# STM32U5G7 register map
File version: 1.3
CPU: CM33 r0p1, little endian, MPU, FPU, 4 interrupt priority bits
Registers are 32-bit, read-write, reset 0x0 unless marked. A register's access mark holds for its fields unless they carry their own. Offsets are from the block's base; [hi:lo] are bit positions; {n}, {i} and the like mark numbered series; 'fields as' and 'values as' point back to an identical list.

## JPEG (part 3 of 3) — JPEG address block description
Base 0x4002A000
Same registers: SEC_JPEG 0x5002A000
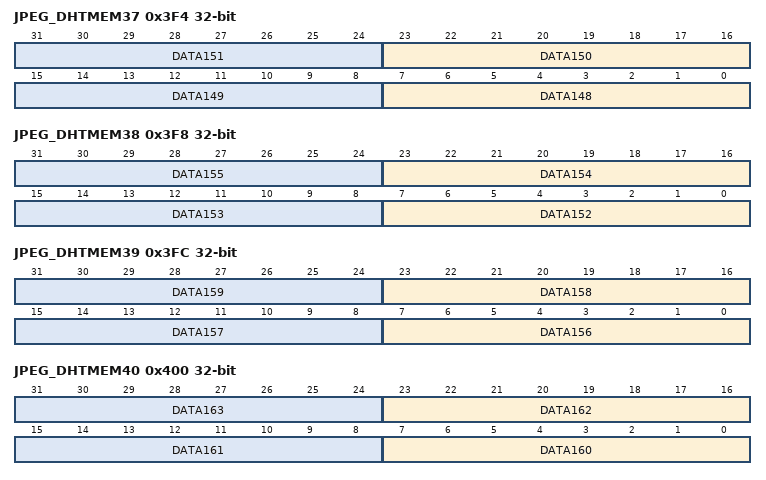
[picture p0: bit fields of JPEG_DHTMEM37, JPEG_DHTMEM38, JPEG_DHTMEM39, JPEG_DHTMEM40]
0x3F4 JPEG_DHTMEM37 reset not defined — For encoding process with header generation, this memory stores the DHT marker segment AC and DC Huffman tables in the ISO/IEC specification format: - DATA0 to DATA27: DC Huffman table0 - DATA28 to DATA205: AC Huffman table0 - DATA206 to DATA233: DC Huffman table1 - DATA234 to DATA411: AC Huffman table1
  [8n-1177:8n-1184] DATA{n} (n=148..151) — Huffman table data {n} Huffman table data for DHT marker segment generation.
0x3F8 JPEG_DHTMEM38 reset not defined — For encoding process with header generation, this memory stores the DHT marker segment AC and DC Huffman tables in the ISO/IEC specification format: - DATA0 to DATA27: DC Huffman table0 - DATA28 to DATA205: AC Huffman table0 - DATA206 to DATA233: DC Huffman table1 - DATA234 to DATA411: AC Huffman table1
  [8n-1209:8n-1216] DATA{n} (n=152..155) — Huffman table data {n} Huffman table data for DHT marker segment generation.
0x3FC JPEG_DHTMEM39 reset not defined — For encoding process with header generation, this memory stores the DHT marker segment AC and DC Huffman tables in the ISO/IEC specification format: - DATA0 to DATA27: DC Huffman table0 - DATA28 to DATA205: AC Huffman table0 - DATA206 to DATA233: DC Huffman table1 - DATA234 to DATA411: AC Huffman table1
  [8n-1241:8n-1248] DATA{n} (n=156..159) — Huffman table data {n} Huffman table data for DHT marker segment generation.
0x400 JPEG_DHTMEM40 reset not defined — For encoding process with header generation, this memory stores the DHT marker segment AC and DC Huffman tables in the ISO/IEC specification format: - DATA0 to DATA27: DC Huffman table0 - DATA28 to DATA205: AC Huffman table0 - DATA206 to DATA233: DC Huffman table1 - DATA234 to DATA411: AC Huffman table1
  [8n-1273:8n-1280] DATA{n} (n=160..163) — Huffman table data {n} Huffman table data for DHT marker segment generation.
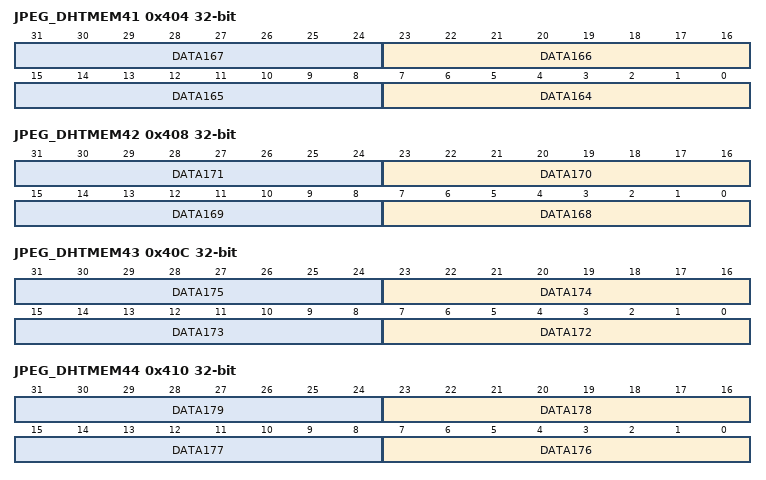
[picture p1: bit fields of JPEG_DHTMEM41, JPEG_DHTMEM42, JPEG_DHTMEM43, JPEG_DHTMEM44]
0x404 JPEG_DHTMEM41 reset not defined — For encoding process with header generation, this memory stores the DHT marker segment AC and DC Huffman tables in the ISO/IEC specification format: - DATA0 to DATA27: DC Huffman table0 - DATA28 to DATA205: AC Huffman table0 - DATA206 to DATA233: DC Huffman table1 - DATA234 to DATA411: AC Huffman table1
  [8n-1305:8n-1312] DATA{n} (n=164..167) — Huffman table data {n} Huffman table data for DHT marker segment generation.
0x408 JPEG_DHTMEM42 reset not defined — For encoding process with header generation, this memory stores the DHT marker segment AC and DC Huffman tables in the ISO/IEC specification format: - DATA0 to DATA27: DC Huffman table0 - DATA28 to DATA205: AC Huffman table0 - DATA206 to DATA233: DC Huffman table1 - DATA234 to DATA411: AC Huffman table1
  [8n-1337:8n-1344] DATA{n} (n=168..171) — Huffman table data {n} Huffman table data for DHT marker segment generation.
0x40C JPEG_DHTMEM43 reset not defined — For encoding process with header generation, this memory stores the DHT marker segment AC and DC Huffman tables in the ISO/IEC specification format: - DATA0 to DATA27: DC Huffman table0 - DATA28 to DATA205: AC Huffman table0 - DATA206 to DATA233: DC Huffman table1 - DATA234 to DATA411: AC Huffman table1
  [8n-1369:8n-1376] DATA{n} (n=172..175) — Huffman table data {n} Huffman table data for DHT marker segment generation.
0x410 JPEG_DHTMEM44 reset not defined — For encoding process with header generation, this memory stores the DHT marker segment AC and DC Huffman tables in the ISO/IEC specification format: - DATA0 to DATA27: DC Huffman table0 - DATA28 to DATA205: AC Huffman table0 - DATA206 to DATA233: DC Huffman table1 - DATA234 to DATA411: AC Huffman table1
  [8n-1401:8n-1408] DATA{n} (n=176..179) — Huffman table data {n} Huffman table data for DHT marker segment generation.
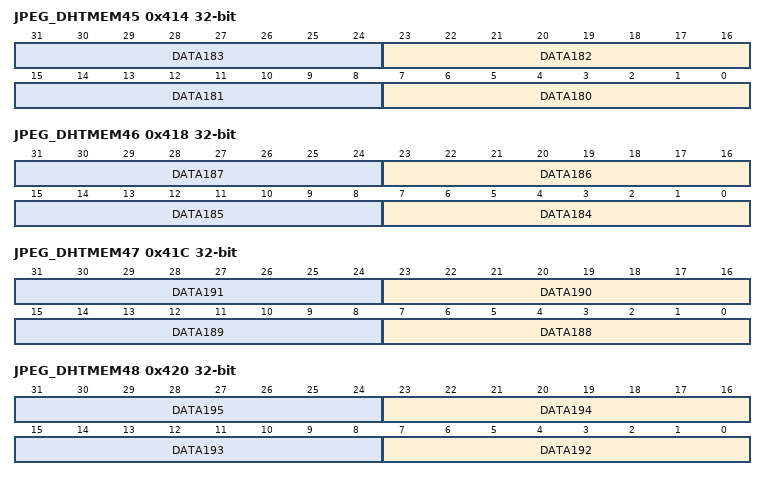
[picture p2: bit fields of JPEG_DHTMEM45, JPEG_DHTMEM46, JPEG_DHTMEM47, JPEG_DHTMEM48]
0x414 JPEG_DHTMEM45 reset not defined — For encoding process with header generation, this memory stores the DHT marker segment AC and DC Huffman tables in the ISO/IEC specification format: - DATA0 to DATA27: DC Huffman table0 - DATA28 to DATA205: AC Huffman table0 - DATA206 to DATA233: DC Huffman table1 - DATA234 to DATA411: AC Huffman table1
  [8n-1433:8n-1440] DATA{n} (n=180..183) — Huffman table data {n} Huffman table data for DHT marker segment generation.
0x418 JPEG_DHTMEM46 reset not defined — For encoding process with header generation, this memory stores the DHT marker segment AC and DC Huffman tables in the ISO/IEC specification format: - DATA0 to DATA27: DC Huffman table0 - DATA28 to DATA205: AC Huffman table0 - DATA206 to DATA233: DC Huffman table1 - DATA234 to DATA411: AC Huffman table1
  [8n-1465:8n-1472] DATA{n} (n=184..187) — Huffman table data {n} Huffman table data for DHT marker segment generation.
0x41C JPEG_DHTMEM47 reset not defined — For encoding process with header generation, this memory stores the DHT marker segment AC and DC Huffman tables in the ISO/IEC specification format: - DATA0 to DATA27: DC Huffman table0 - DATA28 to DATA205: AC Huffman table0 - DATA206 to DATA233: DC Huffman table1 - DATA234 to DATA411: AC Huffman table1
  [8n-1497:8n-1504] DATA{n} (n=188..191) — Huffman table data {n} Huffman table data for DHT marker segment generation.
0x420 JPEG_DHTMEM48 reset not defined — For encoding process with header generation, this memory stores the DHT marker segment AC and DC Huffman tables in the ISO/IEC specification format: - DATA0 to DATA27: DC Huffman table0 - DATA28 to DATA205: AC Huffman table0 - DATA206 to DATA233: DC Huffman table1 - DATA234 to DATA411: AC Huffman table1
  [8n-1529:8n-1536] DATA{n} (n=192..195) — Huffman table data {n} Huffman table data for DHT marker segment generation.
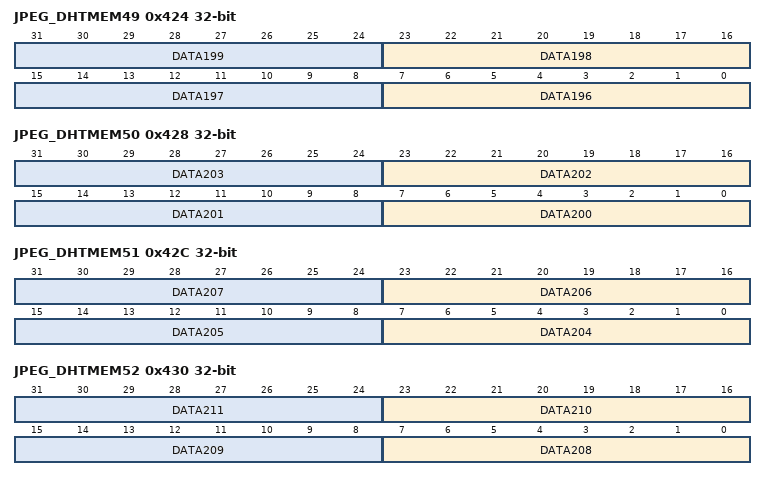
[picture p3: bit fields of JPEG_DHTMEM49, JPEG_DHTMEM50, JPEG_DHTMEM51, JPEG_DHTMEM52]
0x424 JPEG_DHTMEM49 reset not defined — For encoding process with header generation, this memory stores the DHT marker segment AC and DC Huffman tables in the ISO/IEC specification format: - DATA0 to DATA27: DC Huffman table0 - DATA28 to DATA205: AC Huffman table0 - DATA206 to DATA233: DC Huffman table1 - DATA234 to DATA411: AC Huffman table1
  [8n-1561:8n-1568] DATA{n} (n=196..199) — Huffman table data {n} Huffman table data for DHT marker segment generation.
0x428 JPEG_DHTMEM50 reset not defined — For encoding process with header generation, this memory stores the DHT marker segment AC and DC Huffman tables in the ISO/IEC specification format: - DATA0 to DATA27: DC Huffman table0 - DATA28 to DATA205: AC Huffman table0 - DATA206 to DATA233: DC Huffman table1 - DATA234 to DATA411: AC Huffman table1
  [8n-1593:8n-1600] DATA{n} (n=200..203) — Huffman table data {n} Huffman table data for DHT marker segment generation.
0x42C JPEG_DHTMEM51 reset not defined — For encoding process with header generation, this memory stores the DHT marker segment AC and DC Huffman tables in the ISO/IEC specification format: - DATA0 to DATA27: DC Huffman table0 - DATA28 to DATA205: AC Huffman table0 - DATA206 to DATA233: DC Huffman table1 - DATA234 to DATA411: AC Huffman table1
  [8n-1625:8n-1632] DATA{n} (n=204..207) — Huffman table data {n} Huffman table data for DHT marker segment generation.
0x430 JPEG_DHTMEM52 reset not defined — For encoding process with header generation, this memory stores the DHT marker segment AC and DC Huffman tables in the ISO/IEC specification format: - DATA0 to DATA27: DC Huffman table0 - DATA28 to DATA205: AC Huffman table0 - DATA206 to DATA233: DC Huffman table1 - DATA234 to DATA411: AC Huffman table1
  [8n-1657:8n-1664] DATA{n} (n=208..211) — Huffman table data {n} Huffman table data for DHT marker segment generation.
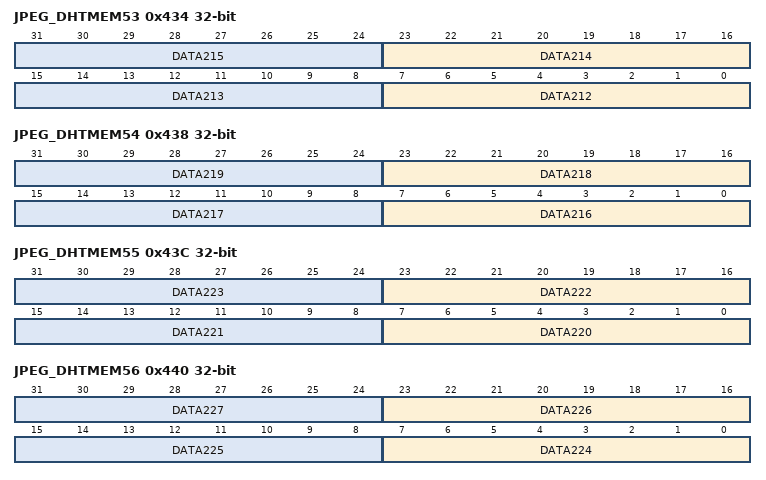
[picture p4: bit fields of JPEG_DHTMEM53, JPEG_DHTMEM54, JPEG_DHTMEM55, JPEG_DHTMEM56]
0x434 JPEG_DHTMEM53 reset not defined — For encoding process with header generation, this memory stores the DHT marker segment AC and DC Huffman tables in the ISO/IEC specification format: - DATA0 to DATA27: DC Huffman table0 - DATA28 to DATA205: AC Huffman table0 - DATA206 to DATA233: DC Huffman table1 - DATA234 to DATA411: AC Huffman table1
  [8n-1689:8n-1696] DATA{n} (n=212..215) — Huffman table data {n} Huffman table data for DHT marker segment generation.
0x438 JPEG_DHTMEM54 reset not defined — For encoding process with header generation, this memory stores the DHT marker segment AC and DC Huffman tables in the ISO/IEC specification format: - DATA0 to DATA27: DC Huffman table0 - DATA28 to DATA205: AC Huffman table0 - DATA206 to DATA233: DC Huffman table1 - DATA234 to DATA411: AC Huffman table1
  [8n-1721:8n-1728] DATA{n} (n=216..219) — Huffman table data {n} Huffman table data for DHT marker segment generation.
0x43C JPEG_DHTMEM55 reset not defined — For encoding process with header generation, this memory stores the DHT marker segment AC and DC Huffman tables in the ISO/IEC specification format: - DATA0 to DATA27: DC Huffman table0 - DATA28 to DATA205: AC Huffman table0 - DATA206 to DATA233: DC Huffman table1 - DATA234 to DATA411: AC Huffman table1
  [8n-1753:8n-1760] DATA{n} (n=220..223) — Huffman table data {n} Huffman table data for DHT marker segment generation.
0x440 JPEG_DHTMEM56 reset not defined — For encoding process with header generation, this memory stores the DHT marker segment AC and DC Huffman tables in the ISO/IEC specification format: - DATA0 to DATA27: DC Huffman table0 - DATA28 to DATA205: AC Huffman table0 - DATA206 to DATA233: DC Huffman table1 - DATA234 to DATA411: AC Huffman table1
  [8n-1785:8n-1792] DATA{n} (n=224..227) — Huffman table data {n} Huffman table data for DHT marker segment generation.
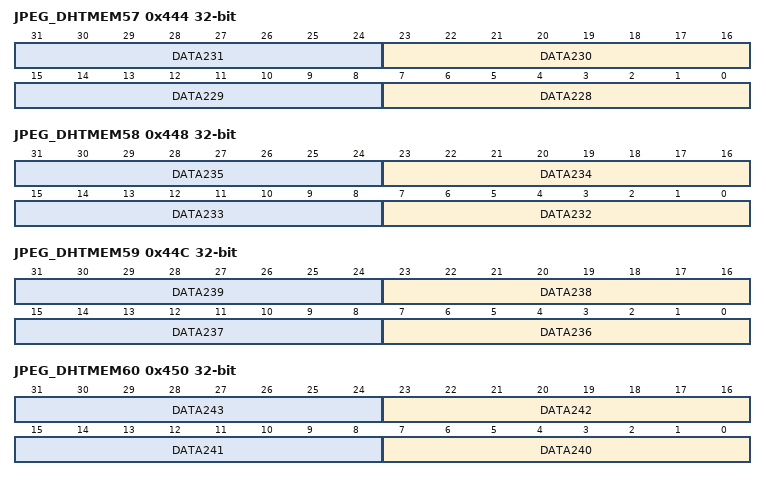
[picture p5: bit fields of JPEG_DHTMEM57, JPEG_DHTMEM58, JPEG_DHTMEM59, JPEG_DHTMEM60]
0x444 JPEG_DHTMEM57 reset not defined — For encoding process with header generation, this memory stores the DHT marker segment AC and DC Huffman tables in the ISO/IEC specification format: - DATA0 to DATA27: DC Huffman table0 - DATA28 to DATA205: AC Huffman table0 - DATA206 to DATA233: DC Huffman table1 - DATA234 to DATA411: AC Huffman table1
  [8n-1817:8n-1824] DATA{n} (n=228..231) — Huffman table data {n} Huffman table data for DHT marker segment generation.
0x448 JPEG_DHTMEM58 reset not defined — For encoding process with header generation, this memory stores the DHT marker segment AC and DC Huffman tables in the ISO/IEC specification format: - DATA0 to DATA27: DC Huffman table0 - DATA28 to DATA205: AC Huffman table0 - DATA206 to DATA233: DC Huffman table1 - DATA234 to DATA411: AC Huffman table1
  [8n-1849:8n-1856] DATA{n} (n=232..235) — Huffman table data {n} Huffman table data for DHT marker segment generation.
0x44C JPEG_DHTMEM59 reset not defined — For encoding process with header generation, this memory stores the DHT marker segment AC and DC Huffman tables in the ISO/IEC specification format: - DATA0 to DATA27: DC Huffman table0 - DATA28 to DATA205: AC Huffman table0 - DATA206 to DATA233: DC Huffman table1 - DATA234 to DATA411: AC Huffman table1
  [8n-1881:8n-1888] DATA{n} (n=236..239) — Huffman table data {n} Huffman table data for DHT marker segment generation.
0x450 JPEG_DHTMEM60 reset not defined — For encoding process with header generation, this memory stores the DHT marker segment AC and DC Huffman tables in the ISO/IEC specification format: - DATA0 to DATA27: DC Huffman table0 - DATA28 to DATA205: AC Huffman table0 - DATA206 to DATA233: DC Huffman table1 - DATA234 to DATA411: AC Huffman table1
  [8n-1913:8n-1920] DATA{n} (n=240..243) — Huffman table data {n} Huffman table data for DHT marker segment generation.
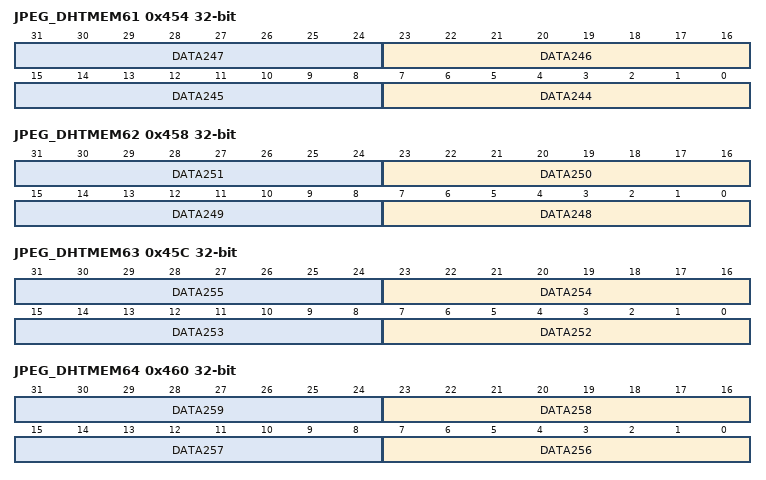
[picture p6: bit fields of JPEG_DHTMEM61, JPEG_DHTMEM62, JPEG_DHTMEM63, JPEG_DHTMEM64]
0x454 JPEG_DHTMEM61 reset not defined — For encoding process with header generation, this memory stores the DHT marker segment AC and DC Huffman tables in the ISO/IEC specification format: - DATA0 to DATA27: DC Huffman table0 - DATA28 to DATA205: AC Huffman table0 - DATA206 to DATA233: DC Huffman table1 - DATA234 to DATA411: AC Huffman table1
  [8n-1945:8n-1952] DATA{n} (n=244..247) — Huffman table data {n} Huffman table data for DHT marker segment generation.
0x458 JPEG_DHTMEM62 reset not defined — For encoding process with header generation, this memory stores the DHT marker segment AC and DC Huffman tables in the ISO/IEC specification format: - DATA0 to DATA27: DC Huffman table0 - DATA28 to DATA205: AC Huffman table0 - DATA206 to DATA233: DC Huffman table1 - DATA234 to DATA411: AC Huffman table1
  [8n-1977:8n-1984] DATA{n} (n=248..251) — Huffman table data {n} Huffman table data for DHT marker segment generation.
0x45C JPEG_DHTMEM63 reset not defined — For encoding process with header generation, this memory stores the DHT marker segment AC and DC Huffman tables in the ISO/IEC specification format: - DATA0 to DATA27: DC Huffman table0 - DATA28 to DATA205: AC Huffman table0 - DATA206 to DATA233: DC Huffman table1 - DATA234 to DATA411: AC Huffman table1
  [8n-2009:8n-2016] DATA{n} (n=252..255) — Huffman table data {n} Huffman table data for DHT marker segment generation.
0x460 JPEG_DHTMEM64 reset not defined — For encoding process with header generation, this memory stores the DHT marker segment AC and DC Huffman tables in the ISO/IEC specification format: - DATA0 to DATA27: DC Huffman table0 - DATA28 to DATA205: AC Huffman table0 - DATA206 to DATA233: DC Huffman table1 - DATA234 to DATA411: AC Huffman table1
  [8n-2041:8n-2048] DATA{n} (n=256..259) — Huffman table data {n} Huffman table data for DHT marker segment generation.
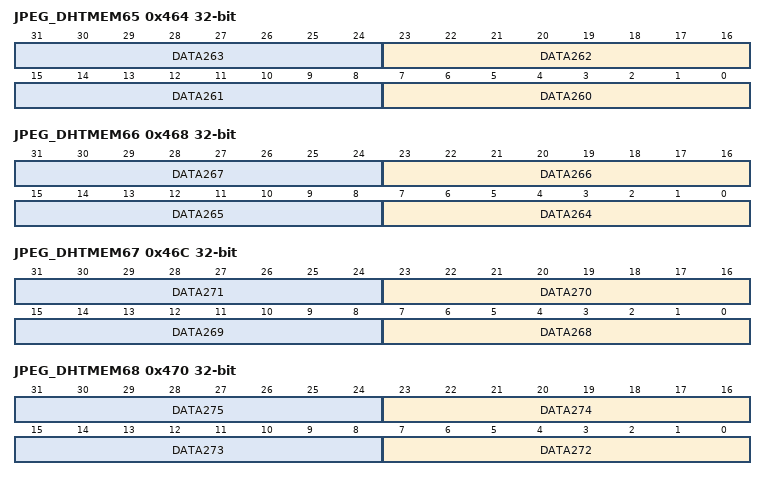
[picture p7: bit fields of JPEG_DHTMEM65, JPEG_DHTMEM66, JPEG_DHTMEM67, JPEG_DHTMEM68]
0x464 JPEG_DHTMEM65 reset not defined — For encoding process with header generation, this memory stores the DHT marker segment AC and DC Huffman tables in the ISO/IEC specification format: - DATA0 to DATA27: DC Huffman table0 - DATA28 to DATA205: AC Huffman table0 - DATA206 to DATA233: DC Huffman table1 - DATA234 to DATA411: AC Huffman table1
  [8n-2073:8n-2080] DATA{n} (n=260..263) — Huffman table data {n} Huffman table data for DHT marker segment generation.
0x468 JPEG_DHTMEM66 reset not defined — For encoding process with header generation, this memory stores the DHT marker segment AC and DC Huffman tables in the ISO/IEC specification format: - DATA0 to DATA27: DC Huffman table0 - DATA28 to DATA205: AC Huffman table0 - DATA206 to DATA233: DC Huffman table1 - DATA234 to DATA411: AC Huffman table1
  [8n-2105:8n-2112] DATA{n} (n=264..267) — Huffman table data {n} Huffman table data for DHT marker segment generation.
0x46C JPEG_DHTMEM67 reset not defined — For encoding process with header generation, this memory stores the DHT marker segment AC and DC Huffman tables in the ISO/IEC specification format: - DATA0 to DATA27: DC Huffman table0 - DATA28 to DATA205: AC Huffman table0 - DATA206 to DATA233: DC Huffman table1 - DATA234 to DATA411: AC Huffman table1
  [8n-2137:8n-2144] DATA{n} (n=268..271) — Huffman table data {n} Huffman table data for DHT marker segment generation.
0x470 JPEG_DHTMEM68 reset not defined — For encoding process with header generation, this memory stores the DHT marker segment AC and DC Huffman tables in the ISO/IEC specification format: - DATA0 to DATA27: DC Huffman table0 - DATA28 to DATA205: AC Huffman table0 - DATA206 to DATA233: DC Huffman table1 - DATA234 to DATA411: AC Huffman table1
  [8n-2169:8n-2176] DATA{n} (n=272..275) — Huffman table data {n} Huffman table data for DHT marker segment generation.
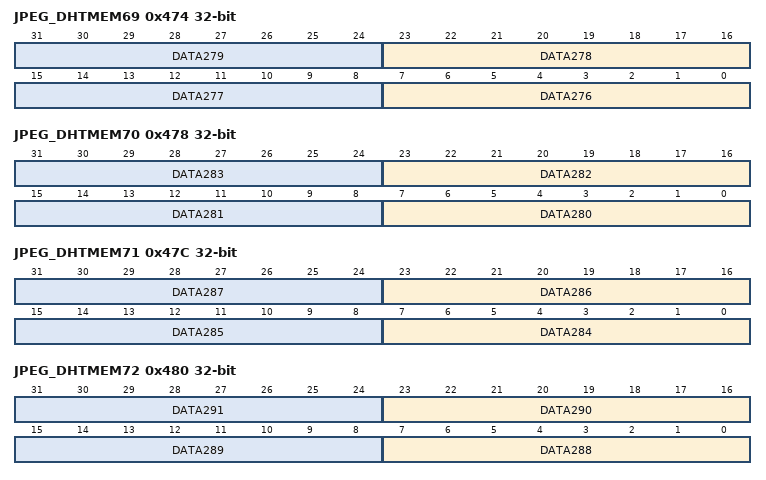
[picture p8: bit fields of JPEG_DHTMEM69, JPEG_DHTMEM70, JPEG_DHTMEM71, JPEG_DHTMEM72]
0x474 JPEG_DHTMEM69 reset not defined — For encoding process with header generation, this memory stores the DHT marker segment AC and DC Huffman tables in the ISO/IEC specification format: - DATA0 to DATA27: DC Huffman table0 - DATA28 to DATA205: AC Huffman table0 - DATA206 to DATA233: DC Huffman table1 - DATA234 to DATA411: AC Huffman table1
  [8n-2201:8n-2208] DATA{n} (n=276..279) — Huffman table data {n} Huffman table data for DHT marker segment generation.
0x478 JPEG_DHTMEM70 reset not defined — For encoding process with header generation, this memory stores the DHT marker segment AC and DC Huffman tables in the ISO/IEC specification format: - DATA0 to DATA27: DC Huffman table0 - DATA28 to DATA205: AC Huffman table0 - DATA206 to DATA233: DC Huffman table1 - DATA234 to DATA411: AC Huffman table1
  [8n-2233:8n-2240] DATA{n} (n=280..283) — Huffman table data {n} Huffman table data for DHT marker segment generation.
0x47C JPEG_DHTMEM71 reset not defined — For encoding process with header generation, this memory stores the DHT marker segment AC and DC Huffman tables in the ISO/IEC specification format: - DATA0 to DATA27: DC Huffman table0 - DATA28 to DATA205: AC Huffman table0 - DATA206 to DATA233: DC Huffman table1 - DATA234 to DATA411: AC Huffman table1
  [8n-2265:8n-2272] DATA{n} (n=284..287) — Huffman table data {n} Huffman table data for DHT marker segment generation.
0x480 JPEG_DHTMEM72 reset not defined — For encoding process with header generation, this memory stores the DHT marker segment AC and DC Huffman tables in the ISO/IEC specification format: - DATA0 to DATA27: DC Huffman table0 - DATA28 to DATA205: AC Huffman table0 - DATA206 to DATA233: DC Huffman table1 - DATA234 to DATA411: AC Huffman table1
  [8n-2297:8n-2304] DATA{n} (n=288..291) — Huffman table data {n} Huffman table data for DHT marker segment generation.
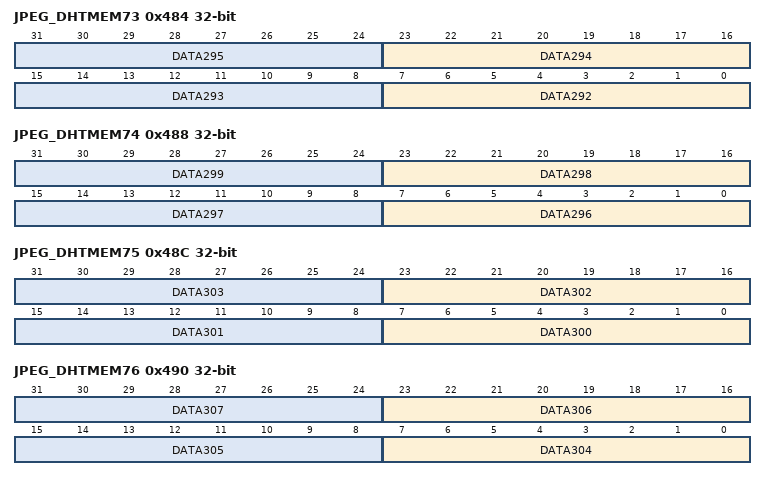
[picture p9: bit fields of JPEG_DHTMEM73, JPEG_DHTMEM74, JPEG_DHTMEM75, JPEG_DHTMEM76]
0x484 JPEG_DHTMEM73 reset not defined — For encoding process with header generation, this memory stores the DHT marker segment AC and DC Huffman tables in the ISO/IEC specification format: - DATA0 to DATA27: DC Huffman table0 - DATA28 to DATA205: AC Huffman table0 - DATA206 to DATA233: DC Huffman table1 - DATA234 to DATA411: AC Huffman table1
  [8n-2329:8n-2336] DATA{n} (n=292..295) — Huffman table data {n} Huffman table data for DHT marker segment generation.
0x488 JPEG_DHTMEM74 reset not defined — For encoding process with header generation, this memory stores the DHT marker segment AC and DC Huffman tables in the ISO/IEC specification format: - DATA0 to DATA27: DC Huffman table0 - DATA28 to DATA205: AC Huffman table0 - DATA206 to DATA233: DC Huffman table1 - DATA234 to DATA411: AC Huffman table1
  [8n-2361:8n-2368] DATA{n} (n=296..299) — Huffman table data {n} Huffman table data for DHT marker segment generation.
0x48C JPEG_DHTMEM75 reset not defined — For encoding process with header generation, this memory stores the DHT marker segment AC and DC Huffman tables in the ISO/IEC specification format: - DATA0 to DATA27: DC Huffman table0 - DATA28 to DATA205: AC Huffman table0 - DATA206 to DATA233: DC Huffman table1 - DATA234 to DATA411: AC Huffman table1
  [8n-2393:8n-2400] DATA{n} (n=300..303) — Huffman table data {n} Huffman table data for DHT marker segment generation.
0x490 JPEG_DHTMEM76 reset not defined — For encoding process with header generation, this memory stores the DHT marker segment AC and DC Huffman tables in the ISO/IEC specification format: - DATA0 to DATA27: DC Huffman table0 - DATA28 to DATA205: AC Huffman table0 - DATA206 to DATA233: DC Huffman table1 - DATA234 to DATA411: AC Huffman table1
  [8n-2425:8n-2432] DATA{n} (n=304..307) — Huffman table data {n} Huffman table data for DHT marker segment generation.
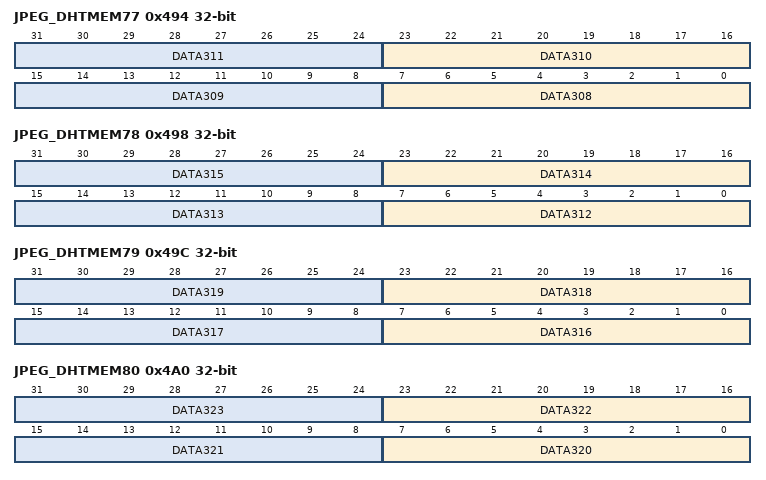
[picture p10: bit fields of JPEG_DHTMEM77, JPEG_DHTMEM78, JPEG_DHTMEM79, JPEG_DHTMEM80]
0x494 JPEG_DHTMEM77 reset not defined — For encoding process with header generation, this memory stores the DHT marker segment AC and DC Huffman tables in the ISO/IEC specification format: - DATA0 to DATA27: DC Huffman table0 - DATA28 to DATA205: AC Huffman table0 - DATA206 to DATA233: DC Huffman table1 - DATA234 to DATA411: AC Huffman table1
  [8n-2457:8n-2464] DATA{n} (n=308..311) — Huffman table data {n} Huffman table data for DHT marker segment generation.
0x498 JPEG_DHTMEM78 reset not defined — For encoding process with header generation, this memory stores the DHT marker segment AC and DC Huffman tables in the ISO/IEC specification format: - DATA0 to DATA27: DC Huffman table0 - DATA28 to DATA205: AC Huffman table0 - DATA206 to DATA233: DC Huffman table1 - DATA234 to DATA411: AC Huffman table1
  [8n-2489:8n-2496] DATA{n} (n=312..315) — Huffman table data {n} Huffman table data for DHT marker segment generation.
0x49C JPEG_DHTMEM79 reset not defined — For encoding process with header generation, this memory stores the DHT marker segment AC and DC Huffman tables in the ISO/IEC specification format: - DATA0 to DATA27: DC Huffman table0 - DATA28 to DATA205: AC Huffman table0 - DATA206 to DATA233: DC Huffman table1 - DATA234 to DATA411: AC Huffman table1
  [8n-2521:8n-2528] DATA{n} (n=316..319) — Huffman table data {n} Huffman table data for DHT marker segment generation.
0x4A0 JPEG_DHTMEM80 reset not defined — For encoding process with header generation, this memory stores the DHT marker segment AC and DC Huffman tables in the ISO/IEC specification format: - DATA0 to DATA27: DC Huffman table0 - DATA28 to DATA205: AC Huffman table0 - DATA206 to DATA233: DC Huffman table1 - DATA234 to DATA411: AC Huffman table1
  [8n-2553:8n-2560] DATA{n} (n=320..323) — Huffman table data {n} Huffman table data for DHT marker segment generation.
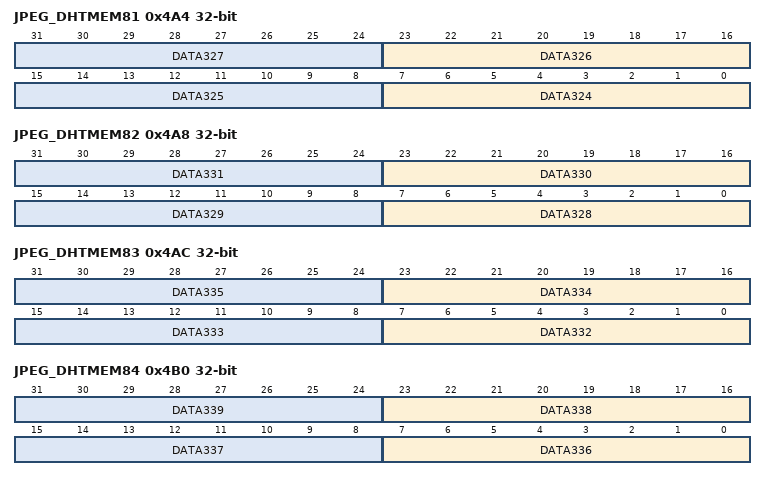
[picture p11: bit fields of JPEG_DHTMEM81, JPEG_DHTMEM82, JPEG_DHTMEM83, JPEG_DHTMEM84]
0x4A4 JPEG_DHTMEM81 reset not defined — For encoding process with header generation, this memory stores the DHT marker segment AC and DC Huffman tables in the ISO/IEC specification format: - DATA0 to DATA27: DC Huffman table0 - DATA28 to DATA205: AC Huffman table0 - DATA206 to DATA233: DC Huffman table1 - DATA234 to DATA411: AC Huffman table1
  [8n-2585:8n-2592] DATA{n} (n=324..327) — Huffman table data {n} Huffman table data for DHT marker segment generation.
0x4A8 JPEG_DHTMEM82 reset not defined — For encoding process with header generation, this memory stores the DHT marker segment AC and DC Huffman tables in the ISO/IEC specification format: - DATA0 to DATA27: DC Huffman table0 - DATA28 to DATA205: AC Huffman table0 - DATA206 to DATA233: DC Huffman table1 - DATA234 to DATA411: AC Huffman table1
  [8n-2617:8n-2624] DATA{n} (n=328..331) — Huffman table data {n} Huffman table data for DHT marker segment generation.
0x4AC JPEG_DHTMEM83 reset not defined — For encoding process with header generation, this memory stores the DHT marker segment AC and DC Huffman tables in the ISO/IEC specification format: - DATA0 to DATA27: DC Huffman table0 - DATA28 to DATA205: AC Huffman table0 - DATA206 to DATA233: DC Huffman table1 - DATA234 to DATA411: AC Huffman table1
  [8n-2649:8n-2656] DATA{n} (n=332..335) — Huffman table data {n} Huffman table data for DHT marker segment generation.
0x4B0 JPEG_DHTMEM84 reset not defined — For encoding process with header generation, this memory stores the DHT marker segment AC and DC Huffman tables in the ISO/IEC specification format: - DATA0 to DATA27: DC Huffman table0 - DATA28 to DATA205: AC Huffman table0 - DATA206 to DATA233: DC Huffman table1 - DATA234 to DATA411: AC Huffman table1
  [8n-2681:8n-2688] DATA{n} (n=336..339) — Huffman table data {n} Huffman table data for DHT marker segment generation.
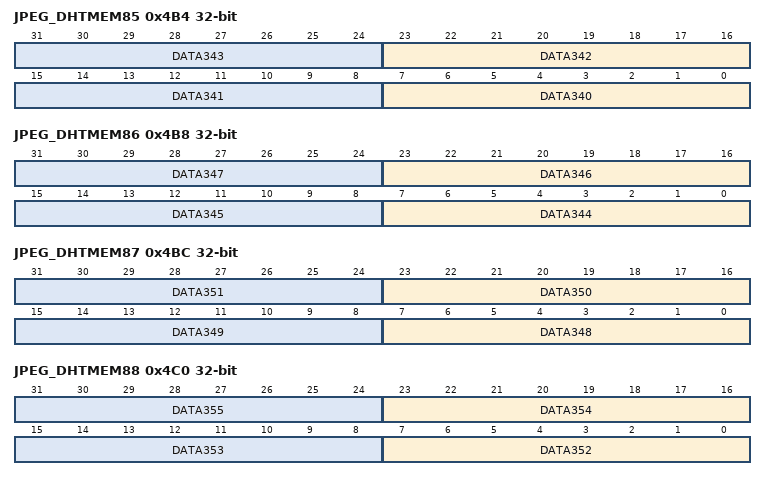
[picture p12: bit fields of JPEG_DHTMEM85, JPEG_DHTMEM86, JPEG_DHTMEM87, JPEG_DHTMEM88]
0x4B4 JPEG_DHTMEM85 reset not defined — For encoding process with header generation, this memory stores the DHT marker segment AC and DC Huffman tables in the ISO/IEC specification format: - DATA0 to DATA27: DC Huffman table0 - DATA28 to DATA205: AC Huffman table0 - DATA206 to DATA233: DC Huffman table1 - DATA234 to DATA411: AC Huffman table1
  [8n-2713:8n-2720] DATA{n} (n=340..343) — Huffman table data {n} Huffman table data for DHT marker segment generation.
0x4B8 JPEG_DHTMEM86 reset not defined — For encoding process with header generation, this memory stores the DHT marker segment AC and DC Huffman tables in the ISO/IEC specification format: - DATA0 to DATA27: DC Huffman table0 - DATA28 to DATA205: AC Huffman table0 - DATA206 to DATA233: DC Huffman table1 - DATA234 to DATA411: AC Huffman table1
  [8n-2745:8n-2752] DATA{n} (n=344..347) — Huffman table data {n} Huffman table data for DHT marker segment generation.
0x4BC JPEG_DHTMEM87 reset not defined — For encoding process with header generation, this memory stores the DHT marker segment AC and DC Huffman tables in the ISO/IEC specification format: - DATA0 to DATA27: DC Huffman table0 - DATA28 to DATA205: AC Huffman table0 - DATA206 to DATA233: DC Huffman table1 - DATA234 to DATA411: AC Huffman table1
  [8n-2777:8n-2784] DATA{n} (n=348..351) — Huffman table data {n} Huffman table data for DHT marker segment generation.
0x4C0 JPEG_DHTMEM88 reset not defined — For encoding process with header generation, this memory stores the DHT marker segment AC and DC Huffman tables in the ISO/IEC specification format: - DATA0 to DATA27: DC Huffman table0 - DATA28 to DATA205: AC Huffman table0 - DATA206 to DATA233: DC Huffman table1 - DATA234 to DATA411: AC Huffman table1
  [8n-2809:8n-2816] DATA{n} (n=352..355) — Huffman table data {n} Huffman table data for DHT marker segment generation.
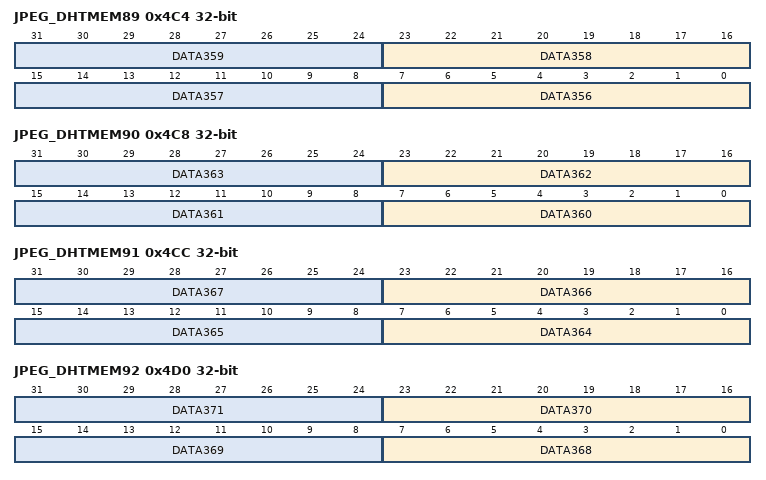
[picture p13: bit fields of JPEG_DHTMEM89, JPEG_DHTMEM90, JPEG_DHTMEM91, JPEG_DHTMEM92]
0x4C4 JPEG_DHTMEM89 reset not defined — For encoding process with header generation, this memory stores the DHT marker segment AC and DC Huffman tables in the ISO/IEC specification format: - DATA0 to DATA27: DC Huffman table0 - DATA28 to DATA205: AC Huffman table0 - DATA206 to DATA233: DC Huffman table1 - DATA234 to DATA411: AC Huffman table1
  [8n-2841:8n-2848] DATA{n} (n=356..359) — Huffman table data {n} Huffman table data for DHT marker segment generation.
0x4C8 JPEG_DHTMEM90 reset not defined — For encoding process with header generation, this memory stores the DHT marker segment AC and DC Huffman tables in the ISO/IEC specification format: - DATA0 to DATA27: DC Huffman table0 - DATA28 to DATA205: AC Huffman table0 - DATA206 to DATA233: DC Huffman table1 - DATA234 to DATA411: AC Huffman table1
  [8n-2873:8n-2880] DATA{n} (n=360..363) — Huffman table data {n} Huffman table data for DHT marker segment generation.
0x4CC JPEG_DHTMEM91 reset not defined — For encoding process with header generation, this memory stores the DHT marker segment AC and DC Huffman tables in the ISO/IEC specification format: - DATA0 to DATA27: DC Huffman table0 - DATA28 to DATA205: AC Huffman table0 - DATA206 to DATA233: DC Huffman table1 - DATA234 to DATA411: AC Huffman table1
  [8n-2905:8n-2912] DATA{n} (n=364..367) — Huffman table data {n} Huffman table data for DHT marker segment generation.
0x4D0 JPEG_DHTMEM92 reset not defined — For encoding process with header generation, this memory stores the DHT marker segment AC and DC Huffman tables in the ISO/IEC specification format: - DATA0 to DATA27: DC Huffman table0 - DATA28 to DATA205: AC Huffman table0 - DATA206 to DATA233: DC Huffman table1 - DATA234 to DATA411: AC Huffman table1
  [8n-2937:8n-2944] DATA{n} (n=368..371) — Huffman table data {n} Huffman table data for DHT marker segment generation.
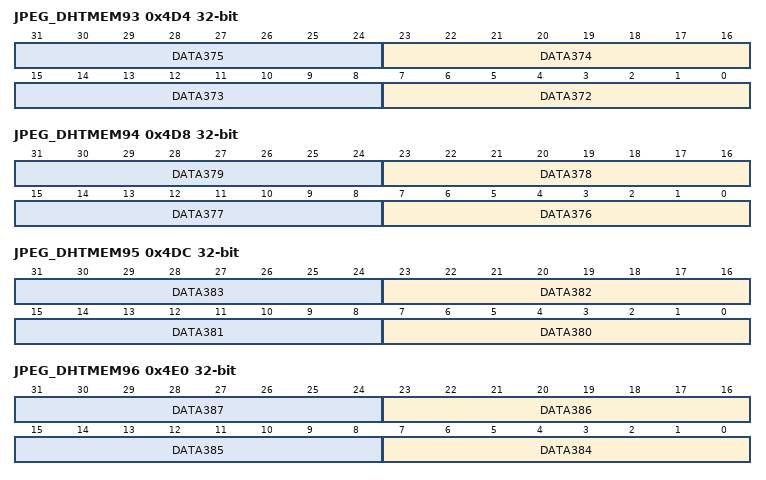
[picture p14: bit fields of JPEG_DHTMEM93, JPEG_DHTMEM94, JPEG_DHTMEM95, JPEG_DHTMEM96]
0x4D4 JPEG_DHTMEM93 reset not defined — For encoding process with header generation, this memory stores the DHT marker segment AC and DC Huffman tables in the ISO/IEC specification format: - DATA0 to DATA27: DC Huffman table0 - DATA28 to DATA205: AC Huffman table0 - DATA206 to DATA233: DC Huffman table1 - DATA234 to DATA411: AC Huffman table1
  [8n-2969:8n-2976] DATA{n} (n=372..375) — Huffman table data {n} Huffman table data for DHT marker segment generation.
0x4D8 JPEG_DHTMEM94 reset not defined — For encoding process with header generation, this memory stores the DHT marker segment AC and DC Huffman tables in the ISO/IEC specification format: - DATA0 to DATA27: DC Huffman table0 - DATA28 to DATA205: AC Huffman table0 - DATA206 to DATA233: DC Huffman table1 - DATA234 to DATA411: AC Huffman table1
  [8n-3001:8n-3008] DATA{n} (n=376..379) — Huffman table data {n} Huffman table data for DHT marker segment generation.
0x4DC JPEG_DHTMEM95 reset not defined — For encoding process with header generation, this memory stores the DHT marker segment AC and DC Huffman tables in the ISO/IEC specification format: - DATA0 to DATA27: DC Huffman table0 - DATA28 to DATA205: AC Huffman table0 - DATA206 to DATA233: DC Huffman table1 - DATA234 to DATA411: AC Huffman table1
  [8n-3033:8n-3040] DATA{n} (n=380..383) — Huffman table data {n} Huffman table data for DHT marker segment generation.
0x4E0 JPEG_DHTMEM96 reset not defined — For encoding process with header generation, this memory stores the DHT marker segment AC and DC Huffman tables in the ISO/IEC specification format: - DATA0 to DATA27: DC Huffman table0 - DATA28 to DATA205: AC Huffman table0 - DATA206 to DATA233: DC Huffman table1 - DATA234 to DATA411: AC Huffman table1
  [8n-3065:8n-3072] DATA{n} (n=384..387) — Huffman table data {n} Huffman table data for DHT marker segment generation.
0x4E4 JPEG_DHTMEM97 reset not defined — For encoding process with header generation, this memory stores the DHT marker segment AC and DC Huffman tables in the ISO/IEC specification format: - DATA0 to DATA27: DC Huffman table0 - DATA28 to DATA205: AC Huffman table0 - DATA206 to DATA233: DC Huffman table1 - DATA234 to DATA411: AC Huffman table1
  [8n-3097:8n-3104] DATA{n} (n=388..391) — Huffman table data {n} Huffman table data for DHT marker segment generation.
0x4E8 JPEG_DHTMEM98 reset not defined — For encoding process with header generation, this memory stores the DHT marker segment AC and DC Huffman tables in the ISO/IEC specification format: - DATA0 to DATA27: DC Huffman table0 - DATA28 to DATA205: AC Huffman table0 - DATA206 to DATA233: DC Huffman table1 - DATA234 to DATA411: AC Huffman table1
  [8n-3129:8n-3136] DATA{n} (n=392..395) — Huffman table data {n} Huffman table data for DHT marker segment generation.
0x4EC JPEG_DHTMEM99 reset not defined — For encoding process with header generation, this memory stores the DHT marker segment AC and DC Huffman tables in the ISO/IEC specification format: - DATA0 to DATA27: DC Huffman table0 - DATA28 to DATA205: AC Huffman table0 - DATA206 to DATA233: DC Huffman table1 - DATA234 to DATA411: AC Huffman table1
  [8n-3161:8n-3168] DATA{n} (n=396..399) — Huffman table data {n} Huffman table data for DHT marker segment generation.
0x4F0 JPEG_DHTMEM100 reset not defined — For encoding process with header generation, this memory stores the DHT marker segment AC and DC Huffman tables in the ISO/IEC specification format: - DATA0 to DATA27: DC Huffman table0 - DATA28 to DATA205: AC Huffman table0 - DATA206 to DATA233: DC Huffman table1 - DATA234 to DATA411: AC Huffman table1
  [8n-3193:8n-3200] DATA{n} (n=400..403) — Huffman table data {n} Huffman table data for DHT marker segment generation.
0x4F4 JPEG_DHTMEM101 reset not defined — For encoding process with header generation, this memory stores the DHT marker segment AC and DC Huffman tables in the ISO/IEC specification format: - DATA0 to DATA27: DC Huffman table0 - DATA28 to DATA205: AC Huffman table0 - DATA206 to DATA233: DC Huffman table1 - DATA234 to DATA411: AC Huffman table1
  [8n-3225:8n-3232] DATA{n} (n=404..407) — Huffman table data {n} Huffman table data for DHT marker segment generation.
0x4F8 JPEG_DHTMEM102 reset not defined — For encoding process with header generation, this memory stores the DHT marker segment AC and DC Huffman tables in the ISO/IEC specification format: - DATA0 to DATA27: DC Huffman table0 - DATA28 to DATA205: AC Huffman table0 - DATA206 to DATA233: DC Huffman table1 - DATA234 to DATA411: AC Huffman table1
  [8n-3257:8n-3264] DATA{n} (n=408..411) — Huffman table data {n} Huffman table data for DHT marker segment generation.
{0x500+4i} JPEG_HUFFENC_AC0_{i} reset not defined (i=0..87) — This memory defines the Huffman codes used during the encoding process of AC components.
  [27:24] HLEN{2i+1} — Huffman length {2i+1} Number of bits in the Huffman code HCODE{2i+1} minus 1.
  [23:16] HCODE{2i+1} — Huffman code {2i+1} 8 least significant bits of the Huffman code. If the Huffman code is less than 8 bits long, the unused bits must be 0.
  [11:8] HLEN{2i} — Huffman length {2i} Number of bits in the Huffman code HCODE{2i} minus 1.
  [7:0] HCODE{2i} — Huffman code {2i} 8 least significant bits of the Huffman code. If the Huffman code is less than 8 bits long, the unused bits must be 0.
{0x660+4i} JPEG_HUFFENC_AC1_{i} reset not defined (i=0..87) — This memory defines the Huffman codes used during the encoding process of AC components.
  fields as JPEG_HUFFENC_AC0_0
{0x7C0+4i} JPEG_HUFFENC_DC0_{i} reset not defined (i=0..7) — This memory defines the Huffman codes used during the encoding process of DC components.
  fields as JPEG_HUFFENC_AC0_0
{0x7E0+4i} JPEG_HUFFENC_DC1_{i} reset not defined (i=0..7) — This memory defines the Huffman codes used during the encoding process of DC components.
  fields as JPEG_HUFFENC_AC0_0

## Notices in the file
Copyright (c) 2026 STMicroelectronics.
SPDX-License-Identifier: Apache-2.0
Licensed under the Apache License, Version 2.0 (the "License");
you may not use this file except in compliance with the License.
You may obtain a copy of the License at
http://www.apache.org/licenses/LICENSE-2.0
Unless required by applicable law or agreed to in writing, software
distributed under the License is distributed on an "AS IS" BASIS,
WITHOUT WARRANTIES OR CONDITIONS OF ANY KIND, either express or implied.
See the License for the specific language governing permissions and
limitations under the License.
